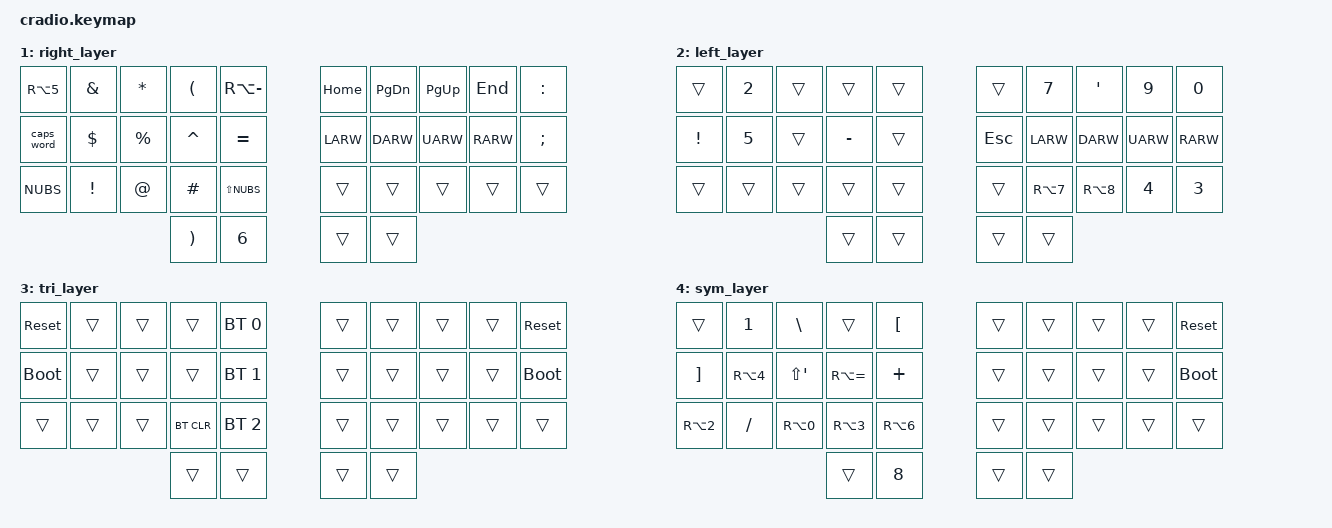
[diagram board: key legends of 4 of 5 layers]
// Copyright (c) 2022 The ZMK Contributors
// SPDX-License-Identifier: MIT

#include <behaviors.dtsi>
#include <dt-bindings/zmk/keys.h>
#include <dt-bindings/zmk/bt.h>

// Home row mods macro
#define HRML(k1,k2,k3,k4) &ht LGUI k1  &ht LALT k2  &ht LCTRL k3  &ht LSHFT k4
#define HRMR(k1,k2,k3,k4) &ht RSHFT k1  &ht RCTRL k2  &ht RALT k3  &ht RGUI k4

/ {
    behaviors {
        ht: hold_tap {
            label = "hold_tap";
            compatible = "zmk,behavior-hold-tap";
            #binding-cells = <2>;
            flavor = "balanced";
            #flavor = "tap-preferred";
            tapping-term-ms = <180>;
            quick-tap-ms = <150>;
            #global-quick-tap;
            bindings = <&kp>, <&kp>;
        };
    };

    combos {
        compatible = "zmk,combos";
        combo_esc {
            timeout-ms = <50>;
            key-positions = <27 28>;
            bindings = <&kp ESC>;
        };
        combo_tab {
            timeout-ms = <50>;
            key-positions = <26 27>;
            bindings = <&kp TAB>;
        };
        combo_e_aigu {
            timeout-ms = <50>;
            key-positions = <4 14>;
            bindings = <&kp N2>;
        };
    };
    
    conditional_layers {
        compatible = "zmk,conditional-layers";
        tri_layer {
            if-layers = <1 2>;
           then-layer = <3>;
        };
    };

    behaviors {
        rev_comm: reverse_shift_comma {
            compatible = "zmk,behavior-mod-morph";
            label = "reverse_shift_comma";
            #binding-cells = <0>;
            bindings = <&kp LT>, <&kp SLASH>;
            mods = <(MOD_LSFT|MOD_RSFT)>;
        };
        semi_dllr: semi_dollar {
            compatible = "zmk,behavior-mod-morph";
            label = "semi_dollar";
            #binding-cells = <0>;
            bindings = <&kp COMMA>, <&kp RBKT>;
            mods = <(MOD_LSFT|MOD_RSFT)>;
        };
    };

    keymap {
        compatible = "zmk,keymap";
        default_layer {
            bindings = <
        //╭──────────┬──────────┬──────────┬──────────┬──────────╮   ╭──────────┬──────────┬──────────┬──────────┬──────────╮
        //│  A       │  Z       │  F       │  P       │  G       │   │  J       │  L       │  U       │  Y       │  M       │
            &kp A      &kp Z      &kp F      &kp P      &kp G          &kp J      &kp L      &kp U      &kp Y      &kp M
        //├──────────┼──────────┼──────────┼──────────┼──────────┤   ├──────────┼──────────┼──────────┼──────────┼──────────┤
        //│  Q       │  R       │  S       │  T       │  D       │   │  H       │  N       │  E       │  I       │ O        │
            HRML(Q,        R,         S,         T)     &kp D          &kp H      HRMR(N,        E,         I,        O)
        //├──────────┼──────────┼──────────┼──────────┼──────────┤   ├──────────┼──────────┼──────────┼──────────┼──────────┤
        //│  W       │  X       │  C       │  V       │  B       │   │  K       │  M       │ . !      │ : /      │    ; $   │
            &kp W      &kp X      &kp C      &kp V      &kp B          &kp K      &kp SEMI  &rev_comm  &kp DOT    &semi_dllr
        //╰──────────┴──────────┴──────────┼──────────┼──────────┤   ├──────────┼──────────┼──────────┴──────────┴──────────╯
                                            &lt 2 TAB   &kp SPACE     &lt 4 BSPC    &lt 1 ENTER
        //                                 ╰──────────┴──────────╯   ╰──────────┴──────────╯
            >;
        };

        right_layer {
            bindings = <
        //╭──────────┬─────────┬──────────┬──────────┬────────────╮   ╭──────────┬──────────┬──────────┬──────────┬──────────╮
        //│     [    │    7    │    8     │     9    │      ]     │   │   HOME   │ PAGE DN  │ PAGE UP  │ END      │  :       │
           &kp RA(N5)  &kp AMPS  &kp STAR   &kp LPAR  &kp RA(MINUS)       &kp HOME   &kp PG_DN  &kp PG_UP  &kp END    &kp COLON
        //├──────────┼─────────┼──────────┼──────────┼────────────┤   ├──────────┼──────────┼──────────┼──────────┼──────────┤
        //│ CAPS     │    4    │    5     │     6    │      =     │   │ LEFT     │ DOWN     │ UP       │ RIGHT    │  ;       │
           &caps_word  &kp DLLR  &kp PRCNT  &kp CARET  &kp EQUAL         &kp LARW   &kp DARW   &kp UARW   &kp RARW   &kp SEMI
        //├──────────┼─────────┼──────────┼──────────┼────────────┤   ├──────────┼──────────┼──────────┼──────────┼──────────┤
        //│    <     │    1    │    2     │     3    │      >     │   │          │          │          │          │          │

            &kp NUBS   &kp EXCL   &kp AT    &kp HASH  &kp LS(NUBS)         &trans     &trans     &trans     &trans     &trans
        //╰──────────┴──────────┴─────────┼──────────┼────────────┤   ├──────────┼──────────┼──────────┴──────────┴──────────╯
        //                                │     0    │     -      │
                                            &kp RPAR     &kp N6        &trans     &trans
        //                                ╰──────────┴────────────╯   ╰──────────┴──────────╯
            >;
        };

        left_layer {
            bindings = <
        //╭──────────┬──────────┬──────────┬──────────┬──────────╮   ╭──────────┬──────────┬──────────┬──────────┬──────────╮
        //│          │  é       │          │          │          │   │          │  è       │  ù       │  ç       │  à       │
            &trans     &kp N2     &trans      &trans     &trans        &trans     &kp N7     &kp SQT    &kp N9     &kp N0
        //├──────────┼──────────┼──────────┼──────────┼──────────┤   ├──────────┼──────────┼──────────┼──────────┼──────────┤
        //│  !       │    (     │          │    )     │          │   │  ESC     │LEFT      │ DOWN     │ UP       │ RIGHT    │
            &kp EXCL   &kp N5     &trans    &kp MINUS   &trans       &kp ESC    &kp LARW   &kp DARW   &kp UARW   &kp RARW
        //├──────────┼──────────┼──────────┼──────────┼──────────┤   ├──────────┼──────────┼──────────┼──────────┼──────────┤
        //│          │          │          │          │          │   │          │    `     │    \     │    '     │    "     │
            &trans     &trans     &trans     &trans     &trans         &trans   &kp RA(N7)  &kp RA(N8)   &kp N4    &kp N3
        //╰──────────┴──────────┴──────────┼──────────┼──────────┤   ├──────────┼──────────┼──────────┴──────────┴──────────╯
                                             &trans     &trans         &trans     &trans
        //                                 ╰──────────┴──────────╯   ╰──────────┴──────────╯
            >;
        };

        tri_layer {
            bindings = <
        //╭──────────┬──────────┬──────────┬──────────┬──────────╮   ╭──────────┬──────────┬──────────┬──────────┬──────────╮
        //│ RESET    │          │          │          │PROFILE 0 │   │          │          │          │          │  RESET   │
           &sys_reset  &trans     &trans     &trans    &bt BT_SEL 0    &trans     &trans     &trans     &trans    &sys_reset
        //├──────────┼──────────┼──────────┼──────────┼──────────┤   ├──────────┼──────────┼──────────┼──────────┼──────────┤
        //│BOOTLOADER│          │          │          │PROFILE 1 │   │          │          │          │          │BOOTLOADER│
          &bootloader  &trans     &trans     &trans    &bt BT_SEL 1    &trans     &trans     &trans     &trans    &bootloader
        //├──────────┼──────────┼──────────┼──────────┼──────────┤   ├──────────┼──────────┼──────────┼──────────┼──────────┤
        //│          │          │          │ CLEAR BT │PROFILE 2 │   │          │          │          │          │          │
            &trans     &trans     &trans    &bt BT_CLR &bt BT_SEL 2    &trans     &trans     &trans     &trans     &trans
        //╰──────────┴──────────┴──────────┼──────────┼──────────┤   ├──────────┼──────────┼──────────┴──────────┴──────────╯
                                             &trans     &trans         &trans     &trans
        //                                 ╰──────────┴──────────╯   ╰──────────┴──────────╯
            >;
        };
        
        sym_layer{
            bindings = <
        //╭──────────┬──────────┬──────────┬──────────┬──────────╮   ╭──────────┬──────────┬──────────┬──────────┬──────────╮
        //│          │    &     │     *    │          │     ^    │   │          │          │          │          │  RESET   │
           &trans       &kp N1    &kp BSLH    &trans    &kp LBKT       &trans     &trans     &trans     &trans    &sys_reset
        //├──────────┼──────────┼──────────┼──────────┼──────────┤   ├──────────┼──────────┼──────────┼──────────┼──────────┤
        //│   $      │    {     │    %     │     }    │    +     │   │          │          │          │          │BOOTLOADER
           &kp RBKT  &kp RA(N4) &kp LS(SQT) &kp RA(EQUAL) &kp PLUS     &trans     &trans     &trans     &trans    &bootloader
        //├──────────┼──────────┼──────────┼──────────┼──────────┤   ├──────────┼──────────┼──────────┼──────────┼──────────┤
        //│   ~      │    !     │    @     │    #     │     |    │   │          │          │          │          │          │
         &kp RA(N2)    &kp SLASH   &kp RA(N0) &kp RA(N3) &kp RA(N6)    &trans     &trans     &trans     &trans     &trans
        //╰──────────┴──────────┴──────────┼──────────┼──────────┤   ├──────────┼──────────┼──────────┴──────────┴──────────╯
        //                                 │          │     _    │
                                             &trans     &kp N8         &trans     &trans
        //                                 ╰──────────┴──────────╯   ╰──────────┴──────────╯
            >;
        };
    };
};
